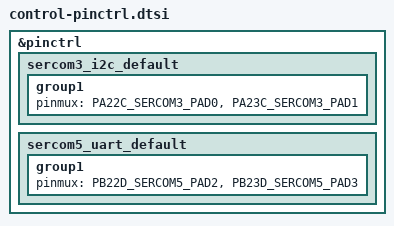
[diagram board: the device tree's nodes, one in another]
/*
 * Copyright (c) 2022, Gerson Fernando Budke <nandojve@gmail.com>
 * SPDX-License-Identifier: Apache-2.0
 */

#include <dt-bindings/pinctrl/samd21-da1jXabcd-pinctrl.h>

&pinctrl {
	sercom3_i2c_default: sercom3_i2c_default {
		group1 {
			pinmux = <PA22C_SERCOM3_PAD0>,
				 <PA23C_SERCOM3_PAD1>;
		};
	};

	sercom5_uart_default: sercom5_uart_default {
		group1 {
			pinmux = <PB22D_SERCOM5_PAD2>,
				 <PB23D_SERCOM5_PAD3>;
		};
	};
};
